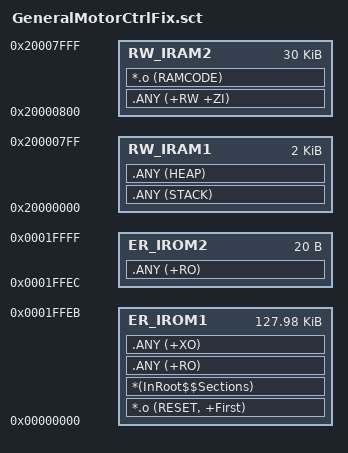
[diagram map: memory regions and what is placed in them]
; *************************************************************
; *** Scatter-Loading Description File generated by uVision ***
; *************************************************************
LR_IROM1 0x00000000 0x0001FFEC  {    ; load region size_region
  ER_IROM1 0x00000000 0x0001FFEC  {  ; load address = execution address
   *.o (RESET, +First)
   *(InRoot$$Sections)
   .ANY (+RO)
   .ANY (+XO)
  }

  RW_IRAM1 0x20000000 0x00000800  {  ; RW data STACK and HEAP for CORE0 and CORE1 >= 2 * (Stack_Size + Heap_Size)
    .ANY (STACK)
    .ANY (HEAP)
  }

  RW_IRAM2 0x20000800 0x00007800  {  ; RW data
   .ANY (+RW +ZI)
   *.o (RAMCODE)
  }
}

LR_IROM2 0x0001FFEC 0x00000014  {
  ER_IROM2 0x0001FFEC 0x00000014  {  ; load address = execution address
   .ANY (+RO)
  }
}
